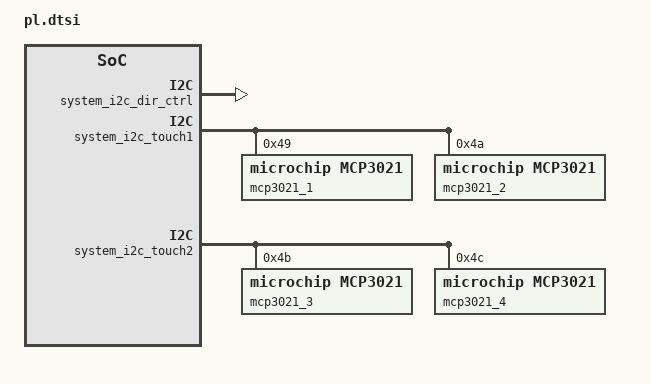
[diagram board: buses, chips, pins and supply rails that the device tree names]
/*
 * CAUTION: This file is automatically generated by Xilinx.
 * Version: XSCT 2021.1
 * Today is: Thu May 26 09:41:25 2022
 */


/ {
	amba_pl: amba_pl@0 {
		#address-cells = <2>;
		#size-cells = <2>;
		compatible = "simple-bus";
		ranges ;
		axi_gpio_0: gpio@802C0000 {
		        #gpio-cells = <2>;
			compatible = "xlnx,xps-gpio-1.00.a";
			gpio-controller ;
			reg = <0x0 0x802C0000 0x0 0x10000 >;
        		xlnx,all-inputs = <0x0>;
        		xlnx,dout-default = <0x01>;
        		xlnx,gpio-width = <32>;
        		xlnx,interrupt-present = <0>;
        		xlnx,is-dual = <0>;
			xlnx,tri-default = <0x0>;
		} ;			
		misc_clk_0: misc_clk_0 {
			#clock-cells = <0>;
			clock-frequency = <299997000>;
			compatible = "fixed-clock";
		};
		system_i2c_dir_ctrl: i2c@80430000 {
			#address-cells = <1>;
			#size-cells = <0>;
			clock-names = "s_axi_aclk";
			clocks = <&misc_clk_0>;
			compatible = "xlnx,axi-iic-2.1", "xlnx,xps-iic-2.00.a";
			interrupt-names = "iic2intc_irpt";
			interrupt-parent = <&gic>;
			interrupts = <0 108 4>;
			reg = <0x0 0x80430000 0x0 0x10000>;
			satus = "okay";
		};
		system_i2c_touch1: i2c@802B0000 {
			#address-cells = <1>;
			#size-cells = <0>;
			clock-names = "s_axi_aclk";
			clocks = <&misc_clk_0>;
			compatible = "xlnx,axi-iic-2.1", "xlnx,xps-iic-2.00.a";
			interrupt-names = "iic2intc_irpt";
			interrupt-parent = <&gic>;
			interrupts = <0 106 4>;
			reg = <0x0 0x802B0000 0x0 0x10000>;
			satus = "okay";
			mcp3021_1@49 {
				compatible = "microchip,mcp3021";
				reg = <0x49>;
				reference-voltage-microvolt = <3300000>; /* 3.3 V */
		        };
			mcp3021_2@4a {
				compatible = "microchip,mcp3021";
				reg = <0x4a>;
				reference-voltage-microvolt = <3300000>; /* 3.3 V */
		        };
		};
		system_i2c_touch2: i2c@803B0000 {
			#address-cells = <1>;
			#size-cells = <0>;
			clock-names = "s_axi_aclk";
			clocks = <&misc_clk_0>;
			compatible = "xlnx,axi-iic-2.1", "xlnx,xps-iic-2.00.a";
			interrupt-names = "iic2intc_irpt";
			interrupt-parent = <&gic>;
			interrupts = <0 104 4>;
			reg = <0x0 0x803B0000 0x0 0x10000>;
			satus = "okay";
			mcp3021_3@4b {
				compatible = "microchip,mcp3021";
				reg = <0x4b>;
				reference-voltage-microvolt = <3300000>; /* 3.3 V */
		        };
			mcp3021_4@4c {
				compatible = "microchip,mcp3021";
				reg = <0x4c>;
				reference-voltage-microvolt = <3300000>; /* 3.3 V */
		        };
		};
	};
};
